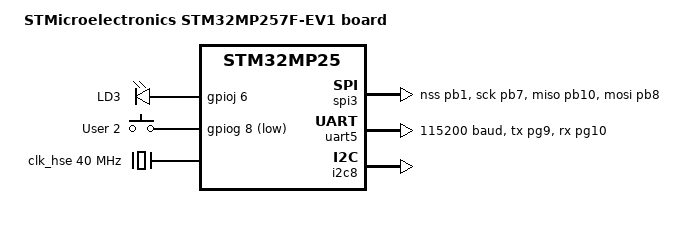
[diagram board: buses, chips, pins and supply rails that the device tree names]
/*
 * Copyright (C) 2025 Savoir-faire Linux, Inc.
 *
 * SPDX-License-Identifier: Apache-2.0
 */

/dts-v1/;
#include <st/mp2/stm32mp257_m33.dtsi>
#include <st/mp2/stm32mp257faix-pinctrl.dtsi>
#include <zephyr/dt-bindings/input/input-event-codes.h>

/ {
	model = "STMicroelectronics STM32MP257F-EV1 board";
	compatible = "st,stm32mp257f-ev1", "st,stm32mp25";

	chosen {
		zephyr,console = &uart5;
		zephyr,shell-uart = &uart5;
		zephyr,flash = &ddr_code;
		zephyr,sram = &ddr_sys;
	};

	leds {
		compatible = "gpio-leds";

		orange_led_3: led_3 {
			gpios = <&gpioj 6 GPIO_ACTIVE_HIGH>;
			label = "LD3";
		};
	};

	gpio_keys {
		compatible = "gpio-keys";

		button_user2: button2 {
			label = "User 2";
			gpios = <&gpiog 8 GPIO_ACTIVE_LOW>;
			zephyr,code = <INPUT_KEY_0>;
		};
	};

	aliases {
		led0 = &orange_led_3;
		sw0 = &button_user2;
	};
};

&clk_hsi {
	status = "okay";
};

&clk_hse {
	clock-frequency = <DT_FREQ_M(40)>;
	status = "okay";
};

&rcc {
	clock-frequency = <DT_FREQ_M(400)>;
};

&gpiog {
	status = "okay";
};

&gpioj {
	status = "okay";
};

&gpioz {
	status = "okay";
};


&spi3 {
	pinctrl-0 = <&spi3_nss_pb1 &spi3_sck_pb7
		     &spi3_miso_pb10 &spi3_mosi_pb8>;
	pinctrl-names = "default";
	status = "okay";
};

&uart5 {
	pinctrl-0 = <&uart5_tx_pg9 &uart5_rx_pg10>;
	pinctrl-names = "default";
	current-speed = <115200>;
	status = "okay";
};

&usart6 {
	pinctrl-0 = <&usart6_tx_pf13 &usart6_rx_pf14>;
	pinctrl-names = "default";
	current-speed = <115200>;
	status = "disabled";
};

&i2c8 {
	pinctrl-0 = <&i2c8_scl_pz4 &i2c8_sda_pz3>;
	pinctrl-names = "default";
	status = "okay";
};
